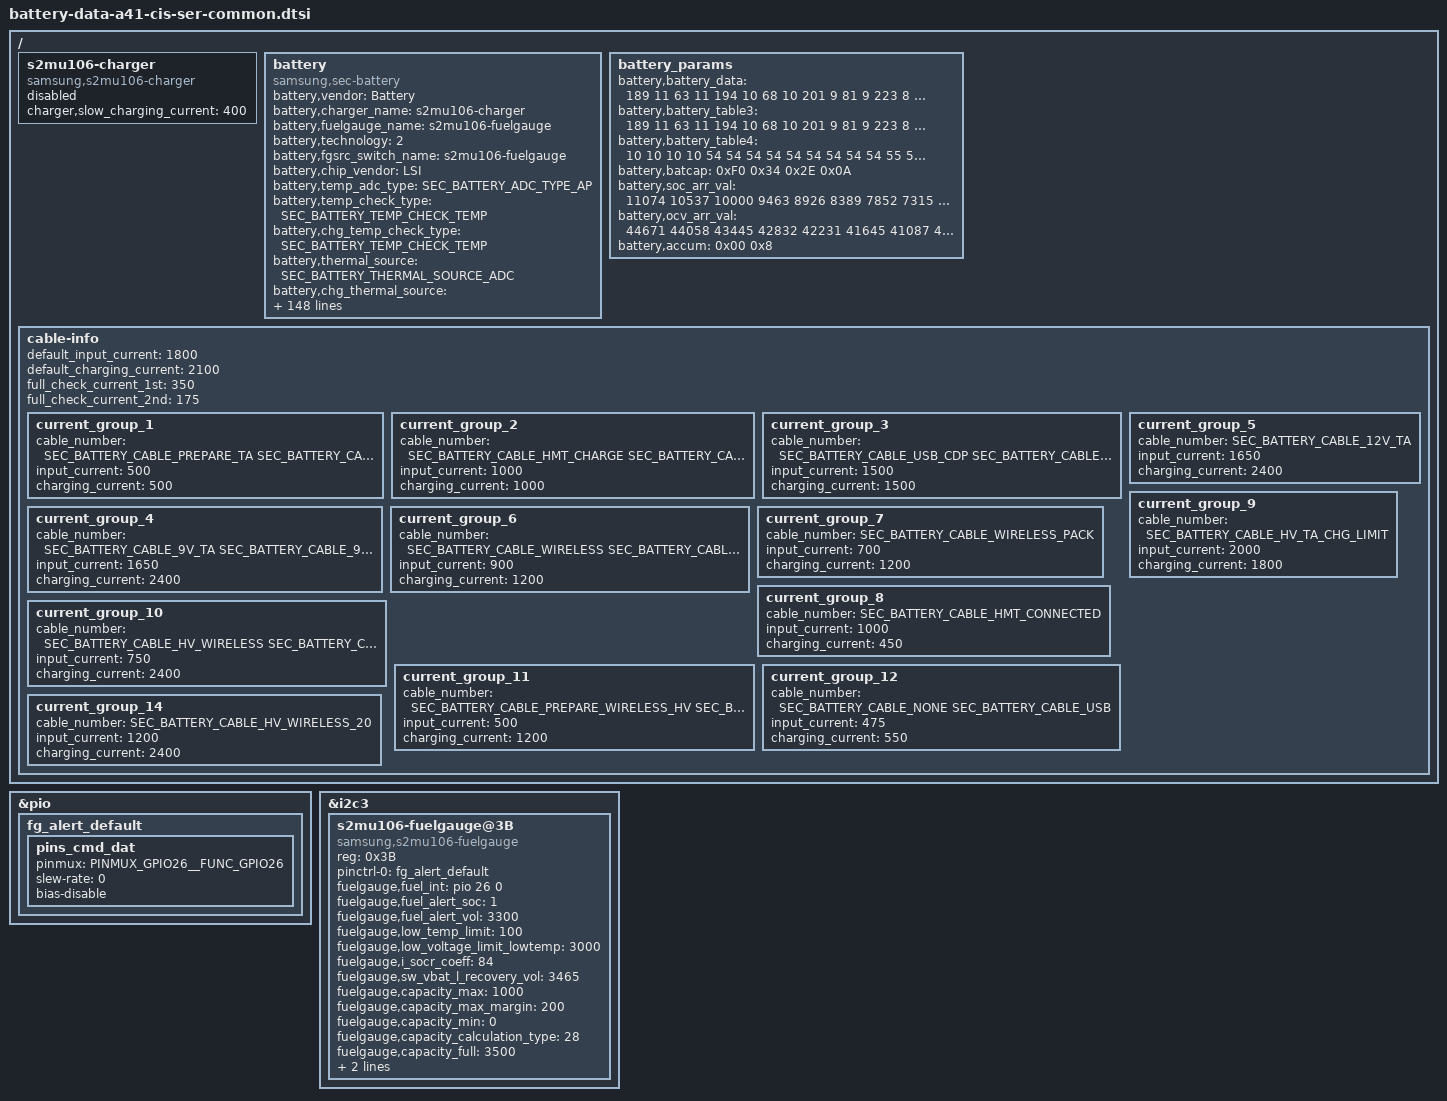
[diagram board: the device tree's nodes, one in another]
/*
 * A41 MTK 2019 Battery parameters device tree file
 *
 * Copyright (C) 2019 Samsung Electronics, Inc.
 *
 * This program is free software: you can redistribute it and/or
 * modify it under the terms of the GNU General Public License
 * as published by the Free Software Foundation; either version 2
 * of the License, or (at your option) any later version.
 *
 * This program is distributed in the hope that it will be useful,
 * but WITHOUT ANY WARRANTY; without even the implied warranty of
 * MERCHANTABILITY or FITNESS FOR A PARTICULAR PURPOSE. See the
 * GNU General Public License for more details.
 *
 * You should have received a copy of the GNU General Public License
 * along with this program. If not, see <http://www.gnu.org/licenses/>.
 *
 */
#include <dt-bindings/battery/sec_battery_param_define.h>

&pio {
	fg_alert_default: fg_alert_default {
		pins_cmd_dat {
			pinmux = <PINMUX_GPIO26__FUNC_GPIO26>;
			slew-rate = <0>;
			bias-disable;
		};
	};
};

&i2c3 {
	s2mu106-fuelgauge@3B {
		status = "okay";
		compatible = "samsung,s2mu106-fuelgauge";
		reg = <0x3B>;
		pinctrl-names = "fg_alrt_default";
		pinctrl-0 = <&fg_alert_default>;
		fuelgauge,fuel_int = <&pio 26 0>;
		fuelgauge,fuel_alert_soc = <1>;
		fuelgauge,fuel_alert_vol = <3300>;
		fuelgauge,low_temp_limit = <100>;
		fuelgauge,low_voltage_limit_lowtemp = <3000>;
		fuelgauge,i_socr_coeff = <84>;
		fuelgauge,sw_vbat_l_recovery_vol = <3465>;
		fuelgauge,capacity_max = <1000>;
		fuelgauge,capacity_max_margin = <200>;
		fuelgauge,capacity_min = <0>;
		fuelgauge,capacity_calculation_type = <28>;
		fuelgauge,capacity_full = <3500>;
		fuelgauge,type_str = "SDI";
		fuelgauge,fg_log_enable = <1>;
	};
};

/ {
	fragment@battery {
		target-path = "/";
		__overlay__ {
			s2mu106-charger {
				status = "disable";
				compatible = "samsung,s2mu106-charger";
				charger,slow_charging_current = <400>;
			};

			battery {
				status = "okay";
				compatible = "samsung,sec-battery";

				pinctrl-names = "default";

				battery,vendor = "Battery";
				battery,charger_name = "s2mu106-charger";
				battery,fuelgauge_name = "s2mu106-fuelgauge";
				battery,technology = <2>; /* POWER_SUPPLY_TECHNOLOGY_LION */
				battery,fgsrc_switch_name = "s2mu106-fuelgauge"; /* Fuelgauge voltage source */

				battery,chip_vendor = "LSI";
				battery,temp_adc_type = <SEC_BATTERY_ADC_TYPE_AP>;

				battery,temp_check_type = <SEC_BATTERY_TEMP_CHECK_TEMP>;
				battery,chg_temp_check_type = <SEC_BATTERY_TEMP_CHECK_TEMP>;

				battery,thermal_source = <SEC_BATTERY_THERMAL_SOURCE_ADC>;
				battery,chg_thermal_source = <SEC_BATTERY_THERMAL_SOURCE_FG>;

				battery,polling_time = <10 30 30 30 3600>;

				battery,temp_table_adc = <
							117 142 196 234 275 323 392 474 568 617
							676 825 922 993 1170 1440 1715 2005 2132 2332
							2522 2672 2962 3335 3584
							>;
				battery,temp_table_data = <
							850 800 700 650 600 550 500 450 400 370
							350 300 270 250 200 150 100 50 30 0
							(-30) (-50) (-100) (-150) (-200)
							>;

				battery,inbat_voltage = <SEC_BATTERY_ADC_TYPE_NONE>;

				battery,adc_check_count = <5>;

				battery,cable_check_type = <SEC_BATTERY_CABLE_CHECK_PSY>;
				battery,cable_source_type = <SEC_BATTERY_CABLE_SOURCE_EXTERNAL>;
				battery,polling_type = <SEC_BATTERY_MONITOR_ALARM>;
				battery,monitor_initial_count = <0>;

				battery,pre_afc_input_current = <500>;
				battery,prepare_afc_delay = <0>;

				battery,battery_check_type = <0>; /* SEC_BATTERY_CHECK_NONE */
				battery,check_count = <0>;

				battery,ovp_uvlo_check_type = <SEC_BATTERY_OVP_UVLO_CHGPOLLING>;

				battery,temp_check_count = <1>;
				battery,overheatlimit_threshold = <700>;
				battery,overheatlimit_recovery = <680>;
				battery,usb_protection_temp = <610>;
				battery,temp_gap_bat_usb = <200>;

				battery,wire_warm_overheat_thresh = <500>;
				battery,wire_normal_warm_thresh = <410>;
				battery,wire_cool1_normal_thresh = <150>;
				battery,wire_cool2_cool1_thresh = <150>;
				battery,wire_cool3_cool2_thresh = <50>;
				battery,wire_cold_cool3_thresh = <0>;

				battery,wireless_warm_overheat_thresh = <450>;
				battery,wireless_normal_warm_thresh = <410>;
				battery,wireless_cool1_normal_thresh = <150>;
				battery,wireless_cool2_cool1_thresh = <150>;
				battery,wireless_cool3_cool2_thresh = <50>;
				battery,wireless_cold_cool3_thresh = <0>;

				battery,wire_warm_current = <1200>;		/* 0.36C */
				battery,wire_cool1_current = <2400>;		/* 0.72C 1st step not used */
				battery,wire_cool2_current = <800>;		/* 0.3C */
				battery,wire_cool3_current = <300>;		/* 0.1C */

				battery,wireless_warm_current = <800>;		/* 0.24C */
				battery,wireless_cool1_current = <2400>;	/* 0.72C */
				battery,wireless_cool2_current = <800>;		/* 0.3C */
				battery,wireless_cool3_current = <450>;		/* 0.1C */

				battery,high_temp_topoff = <175>;
				battery,low_temp_topoff = <175>;
				battery,high_temp_float = <4150>;
				battery,low_temp_float = <4380>;

				battery,swelling_high_rechg_voltage = <4000>;
				battery,swelling_low_rechg_voltage = <4200>;

				battery,full_check_type = <SEC_BATTERY_FULLCHARGED_FG_CURRENT>;
				battery,full_check_type_2nd = <SEC_BATTERY_FULLCHARGED_FG_CURRENT>;
				battery,full_check_count = <1>;
				battery,chg_gpio_full_check = <0>;
				battery,chg_polarity_full_check = <1>;

				battery,chg_heating_prevention_method = <1>; /* SEC_BATTERY_BY_CHANGING_CURRENT */
				battery,chg_high_temp = <460>;
				battery,chg_high_temp_recovery = <440>;
				battery,chg_input_limit_current = <1000>;
				battery,chg_charging_limit_current = <1250>; 

				battery,wpc_high_temp = <410>;
				battery,wpc_high_temp_recovery = <400>;
				battery,wpc_charging_limit_current = <450>;
				battery,wpc_lcd_on_high_temp = <430>;
				battery,wpc_lcd_on_high_temp_rec = <300>;

				battery,wpc_store_high_temp = <410>;
				battery,wpc_store_high_temp_recovery = <400>;
				battery,wpc_store_lcd_on_high_temp = <380>;
				battery,wpc_store_lcd_on_high_temp_rec = <300>;

				battery,sleep_mode_limit_current = <500>;
				battery,wc_full_input_limit_current = <100>;
				battery,wc_cv_current = <820>;
				battery,wc_cv_pack_current = <630>;
				battery,wc_hero_stand_cc_cv = <70>;
				battery,wc_hero_stand_cv_current = <600>;
				battery,wc_hero_stand_hv_cv_current = <450>;

				battery,mix_high_temp = <420>;
				battery,mix_high_chg_temp = <500>;
				battery,mix_high_temp_recovery = <390>;
				
				/* SEC_BATTERY_FULL_CONDITION_SOC |
				* SEC_BATTERY_FULL_CONDITION_NOTIMEFULL |
				* SEC_BATTERY_FULL_CONDITION_VCELL
				*/
				battery,full_condition_type = <13>;
				battery,full_condition_soc = <93>;
				battery,full_condition_vcell = <4280>;

				battery,recharge_check_count = <1>;
				battery,recharge_condition_type = <SEC_BATTERY_RECHARGE_CONDITION_VCELL>;
				battery,recharge_condition_soc = <98>;
				battery,recharge_condition_vcell = <4310>;

				battery,charging_total_time = <14400>;
				battery,hv_charging_total_time = <10800>;
				battery,normal_charging_total_time = <18000>;
				battery,usb_charging_total_time = <36000>;
				battery,recharging_total_time = <5400>;
				battery,charging_reset_time = <0>;
				battery,chg_float_voltage = <4380>;
				battery,chg_float_voltage_conv = <1>;

				battery,siop_event_check_type = <1>;
				battery,siop_call_cv_current = <330>;
				battery,siop_call_cc_current = <330>;

				battery,siop_input_limit_current = <1200>;
				battery,siop_charging_limit_current = <1000>;
				battery,siop_hv_input_limit_current = <700>;
				battery,siop_hv_charging_limit_current = <1000>;

				battery,input_current_by_siop_20 = <1000>;
				battery,hv_input_current_by_siop_20 = <500>;
				battery,input_current_by_siop_10 = <800>;
				battery,hv_input_current_by_siop_10 = <400>;
				battery,input_current_by_siop_0 = <1000>;
				battery,hv_input_current_by_siop_0 = <500>;

				battery,siop_wireless_input_limit_current = <600>;
				battery,siop_wireless_charging_limit_current = <700>;
				battery,siop_hv_wireless_input_limit_current = <600>;
				battery,siop_hv_wireless_charging_limit_current = <700>;
				battery,siop_store_hv_wireless_input_limit_current = <450>;

				battery,ttf_hv_charge_current = <2400>;
				battery,ttf_hv_wireless_charge_current = <1050>;
				battery,ttf_wireless_charge_current = <900>;
				
				battery,rp_current_rp1 = <500>;
				battery,rp_current_rp2 = <1500>;
				battery,rp_current_rp3 = <3000>;
				battery,rp_current_rdu_rp3 = <2100>;
				battery,rp_current_abnormal_rp3 = <1800>;

				battery,pd_charging_charge_power = <15000>;
				battery,max_charging_current = <2400>;
				battery,max_charging_charge_power = <25000>; /* 25W */

				/* cycle, chg_float_voltage, recharge_condition_vcell, full_condition_vcell, full_condition_soc, step charging condition */
				battery,age_data = <0 4380 4310 4280 93
					300 4360 4290 4260 92
					400 4340 4270 4240 91
					700 4320 4250 4220 90
					1000 4270 4200 4170 89>;

				battery,health_condition = <
						/* CYCLE ASOC */
						900 75	/* GOOD */
						1200 65 /* NORMAL */
						1500 55 /* AGED */
						>;

				battery,max_input_voltage = <9000>; /* mV */
				battery,max_input_current = <3000>;  /* mA */

				battery,standard_curr = <2400>;
				battery,expired_time = <10800>; /* 120 + 60 minutes */
				battery,recharging_expired_time = <5400>;
				battery,battery_full_capacity = <3500>;
				battery,cisd_max_voltage_thr = <5000>; /* batttery ovp dettection voltage */
				battery,cisd_alg_index = <8>;
				battery,ignore_cisd_index = <0 960>; /* Do not use AFC_FAIL to DROP_VALUE */
				battery,ignore_cisd_index_d = <0 120>; /* Do not use AFC_FAIL_PER_DAY to DROP_VALUE_PER_DAY */ 

				io-channels = <&auxadc 3>;
				io-channel-names = "adc-temp";
			};

			battery_params {
				battery,battery_data =
					<
					/***** battery data for 4.38 *****/
					/* battery,battery_table3 */
					189 11 63 11 194 10 68 10 201 9
					81 9 223 8 117 8 20 8 190 7
					83 7 247 6 191 6 147 6 112 6
					82 6 41 6 251 5 197 5 141 5
					82 5 182 1 220 8 110 8 0 8
					146 7 36 7 182 6 72 6 218 5
					108 5 254 4 144 4 34 4 180 3
					70 3 216 2 106 2 252 1 142 1
					32 1 178 0 68 0 217 15

					/* battery,battery_table4 */
					10 10 10 10 54 54 54 54 54 54
					54 54 54 55 56 56 57 57 57 59
					61 154

					/* battery,batcap */
					0xF0 0x34 0x2E 0x0A /* [0x0E] [0x0F] [0x10] [0x11] */
					/* battery,accum */
					0x00 0x08 /* [0x44] [0x45] */

					/* battery,soc_arr_val */
					11074 10537 10000 9463 8926 8389 7852 7315 6777 6240
					5703 5166 4629 4091 3554 3017 2480 1943 1406 868
					331 (-191)

					/* battery,ocv_arr_val */
					44671 44058 43445 42832 42231 41645 41087 40570 40098 39676
					39153 38707 38434 38218 38046 37900 37700 37474 37212 36939
					36652 32139

					/* battery,tunning */
					0x00

					/***** battery data for 4.36 *****/
					/* battery,battery_table3 */
					189 11 63 11 194 10 68 10 201 9
					81 9 223 8 117 8 20 8 190 7
					83 7 247 6 191 6 147 6 112 6
					82 6 41 6 251 5 197 5 141 5
					82 5 182 1 255 8 144 8 32 8
					176 7 64 7 209 6 97 6 241 5
					130 5 18 5 162 4 50 4 195 3
					83 3 227 2 116 2 4 2 148 1
					36 1 181 0 69 0 216 15

					/* battery,battery_table4 */
					10 10 10 10 54 54 54 54 54 54
					54 54 54 55 56 56 57 57 57 59
					61 154

					/* battery,batcap */
					0x28 0x32 0x86 0x07  /* [0x0E] [0x0F] [0x10] [0x11] */
					/* battery,accum */
					0x00 0x8 /* [0x44] [0x45] */

					/* battery,soc_arr_val */
					11247 10701 10156 9610 9065 8519 7974 7428 6883 6337
					5792 5246 4701 4155 3610 3064 2519 1973 1428 882
					336 (-194)
					/* battery,ocv_arr_val */
					44671 44058 43445 42832 42231 41645 41087 40570 40098 39676
					39153 38707 38434 38218 38046 37900 37700 37474 37212 36939
					36652 32139

					/* battery,tunning */
					0x00

					/***** battery data for 4.34 *****/
					/* battery,battery_table3 */
					189 11 63 11 194 10 68 10 201 9
					81 9 223 8 117 8 20 8 190 7
					83 7 247 6 191 6 147 6 112 6
					82 6 41 6 251 5 197 5 141 5
					82 5 182 1 39 9 182 8 68 8
					210 7 97 7 239 6 125 6 12 6
					154 5 41 5 183 4 69 4 211 3
					98 3 240 2 126 2 13 2 155 1
					42 1 184 0 70 0 216 15

					/* battery,battery_table4 */
					10 10 10 10 54 54 54 54 54 54
					54 54 54 55 56 56 57 57 57 59
					61 154

					/* battery,batcap */
					0x4C 0x31 0x65 0x07 /* [0x0E] [0x0F] [0x10] [0x11] */
					/* battery,accum */
					0x00 0x8 /* [0x44] [0x45] */

					/* battery,soc_arr_val */
					11442 10887 10332 9778 9223 8668 8113 7558 7003 6448
					5893 5337 4782 4227 3673 3118 2563 2008 1453 897
					342 (-197)
					/* battery,ocv_arr_val */
					44671 44058 43445 42832 42231 41645 41087 40570 40098 39676
					39153 38707 38434 38218 38046 37900 37700 37474 37212 36939
					36652 32139

					/* battery,tunning */
					0x00

					/***** battery data for 4.32 *****/
					/* battery,battery_table3 */
					189 11 63 11 194 10 68 10 201 9
					81 9 223 8 117 8 20 8 190 7
					83 7 247 6 191 6 147 6 112 6
					82 6 41 6 251 5 197 5 141 5
					82 5 182 1 85 9 225 8 109 8
					249 7 133 7 18 7 158 6 42 6
					182 5 66 5 206 4 90 4 230 3
					115 3 255 2 139 2 23 2 163 1
					47 1 187 0 71 0 215 15

					/* battery,battery_table4 */
					10 10 10 10 54 54 54 54 54 54
					54 54 54 55 56 56 57 57 57 59
					61 154

					/* battery,batcap */
					0x5C 0x30 0x41 0x07 /* [0x0E] [0x0F] [0x10] [0x11] */
					/* battery,accum */
					0x00 0x8 /* [0x44] [0x45] */

					/* battery,soc_arr_val */
					11664 11098 10533 9967 9401 8836 8270 7704 7138 6573
					6007 5441 4875 4309 3744 3178 2612 2047 1481 915
					349 (-201)
					/* battery,ocv_arr_val */
					44671 44058 43445 42832 42231 41645 41087 40570 40098 39676
					39153 38707 38434 38218 38046 37900 37700 37474 37212 36939
					36652 32139

					/* battery,tunning */
					0x00

					/***** battery data for 4.27 *****/
					/* battery,battery_table3 */
					189 11 63 11 194 10 68 10 201 9
					81 9 223 8 117 8 20 8 190 7
					83 7 247 6 191 6 147 6 112 6
					82 6 41 6 251 5 197 5 141 5
					82 5 182 1 202 9 81 9 215 8
					93 8 228 7 106 7 241 6 119 6
					254 5 132 5 11 5 145 4 23 4
					158 3 36 3 171 2 49 2 184 1
					62 1 196 0 75 0 213 15

					/* battery,battery_table4 */
					10 10 10 10 54 54 54 54 54 54
					54 54 54 55 56 56 57 57 57 59
					61 154

					/* battery,batcap */
					0x18 0x2E 0xEA 0x06 /* [0x0E] [0x0F] [0x10] [0x11] */
					/* battery,accum */
					0x00 0x8 /* [0x44] [0x45] */

					/* battery,soc_arr_val */
					12237 11643 11050 10456 9863 9269 8676 8082 7489 6895
					6302 5708 5114 4521 3927 3334 2741 2147 1554 959
					366 (-211)
					/* battery,ocv_arr_val */
					44671 44058 43445 42832 42231 41645 41087 40570 40098 39676
					39153 38707 38434 38218 38046 37900 37700 37474 37212 36939
					36652 32139

					/* battery,tunning */
					0x00
				>;

				battery,battery_table3 = <
						189 11 63 11 194 10 68 10 201 9
						81 9 223 8 117 8 20 8 190 7
						83 7 247 6 191 6 147 6 112 6
						82 6 41 6 251 5 197 5 141 5
						82 5 182 1 220 8 110 8 0 8
						146 7 36 7 182 6 72 6 218 5
						108 5 254 4 144 4 34 4 180 3
						70 3 216 2 106 2 252 1 142 1
						32 1 178 0 68 0 217 15
						>;

				battery,battery_table4 = <
						10 10 10 10 54 54 54 54 54 54
						54 54 54 55 56 56 57 57 57 59
						61 154
						>;

				battery,batcap = <0xF0 0x34 0x2E 0x0A>; /* [0x0E] [0x0F] [0x10] [0x11] */

				battery,soc_arr_val = <
							11074 10537 10000 9463 8926 8389 7852 7315 6777 6240
							5703 5166 4629 4091 3554 3017 2480 1943 1406 868
							331 (-191)
							>;
				battery,ocv_arr_val = <
							44671 44058 43445 42832 42231 41645 41087 40570 40098 39676
							39153 38707 38434 38218 38046 37900 37700 37474 37212 36939
							36652 32139
							>;

				battery,accum = <0x00 0x8>; /* 0x44 0x45 */
			};
			/* sec_battery_cable
			 *   0	UNKNOWN,
			 *   1	NONE,
			 *   2	PREPARE_TA,
			 *   3	TA,
			 *   4	USB,
			 *   5	USB_CDP,
			 *   6	9V_TA,
			 *   7	9V_ERR,
			 *   8	9V_UNKNOWN,
			 *   9	12V_TA,
			 *  10	WIRELESS,
			 *  11	HV_WIRELESS,
			 *  12	PMA_WIRELESS,
			 *  13	WIRELESS_PACK,
			 *  14	CABLE_WIRELESS_HV_PACK,
			 *  15	WIRELESS_STAND,
			 *  16	WIRELESS_HV_STAND,
			 *  17	QC20,
			 *  18	QC30,
			 *  19	PDIC,
			 *  20	UARTOFF,
			 *  21	OTG,
			 *  22	LAN_HUB,
			 *  23	POWER_SHARING,
			 *  24	HMT_CONNECTED,
			 *  25	HMT_CHARGE,
			 *  26	HV_TA_CHG_LIMIT,
			 *  27	WIRELESS_VEHICLE,
			 *  28	WIRELESS_HV_VEHICLE,
			 *  29	PREPARE_WIRELESS_HV,
			 *  30  TIMEOUT,
			 *  31  SMART_OTG,
			 *  32  SMART_NOTG,
			 *  33  WIRELESS_TX,
			 *  34	HV_WIRELESS_20,
			 *  35	HV_WIRELESS_20_LIMIT,
			 *  36	WIRELESS_FAKE,
			 *  37  PREPARE_WIRELESS_20,
			 *  38	CABLE_PDIC_APDO,
			 *  39	CABLE_MAX,
			 */
			cable-info {
				default_input_current = <1800>;
				default_charging_current = <2100>;
				full_check_current_1st = <350>;
				full_check_current_2nd = <175>;

				current_group_1 {
					cable_number = <
						SEC_BATTERY_CABLE_PREPARE_TA
						SEC_BATTERY_CABLE_PDIC
						SEC_BATTERY_CABLE_OTG
						SEC_BATTERY_CABLE_LAN_HUB
						SEC_BATTERY_CABLE_POWER_SHARING
						SEC_BATTERY_CABLE_TIMEOUT>;
					input_current = <500>;
					charging_current = <500>;
				};
				current_group_2 {
					cable_number = <
						SEC_BATTERY_CABLE_HMT_CHARGE
						SEC_BATTERY_CABLE_SMART_OTG>;
					input_current = <1000>;
					charging_current = <1000>;
				};
				current_group_3 {
					cable_number = <
						SEC_BATTERY_CABLE_USB_CDP
						SEC_BATTERY_CABLE_SMART_NOTG>;
					input_current = <1500>;
					charging_current = <1500>;
				};
				current_group_4 {
					cable_number = <
						SEC_BATTERY_CABLE_9V_TA
						SEC_BATTERY_CABLE_9V_ERR
						SEC_BATTERY_CABLE_9V_UNKNOWN
						SEC_BATTERY_CABLE_QC20
						SEC_BATTERY_CABLE_QC30>;
					input_current = <1650>;
					charging_current = <2400>;
				};
				current_group_5 {
					cable_number = <SEC_BATTERY_CABLE_12V_TA>;
					input_current = <1650>;
					charging_current = <2400>;
				};
				current_group_6 {
					cable_number = <
						SEC_BATTERY_CABLE_WIRELESS
						SEC_BATTERY_CABLE_PMA_WIRELESS
						SEC_BATTERY_CABLE_WIRELESS_STAND
						SEC_BATTERY_CABLE_WIRELESS_VEHICLE
						SEC_BATTERY_CABLE_WIRELESS_TX
						SEC_BATTERY_CABLE_WIRELESS_FAKE>;
					input_current = <900>;
					charging_current = <1200>;
				};
				current_group_7 {
					cable_number = <SEC_BATTERY_CABLE_WIRELESS_PACK>;
					input_current = <700>;
					charging_current = <1200>;
				};
				current_group_8 {
					cable_number = <SEC_BATTERY_CABLE_HMT_CONNECTED>;
					input_current = <1000>;
					charging_current = <450>;
				};
				current_group_9 {
					cable_number = <SEC_BATTERY_CABLE_HV_TA_CHG_LIMIT>;
					input_current = <2000>;
					charging_current = <1800>;
				};
				current_group_10 {
					cable_number = <
						SEC_BATTERY_CABLE_HV_WIRELESS
						SEC_BATTERY_CABLE_WIRELESS_HV_PACK
						SEC_BATTERY_CABLE_WIRELESS_HV_STAND
						SEC_BATTERY_CABLE_WIRELESS_HV_VEHICLE
						SEC_BATTERY_CABLE_HV_WIRELESS_20_LIMIT>;
					input_current = <750>;
					charging_current = <2400>;
				};
				current_group_11 {
					cable_number = <
						SEC_BATTERY_CABLE_PREPARE_WIRELESS_HV
						SEC_BATTERY_CABLE_PREPARE_WIRELESS_20>;
					input_current = <500>;
					charging_current = <1200>;
				};
				current_group_12 {
					cable_number = <
						SEC_BATTERY_CABLE_NONE
						SEC_BATTERY_CABLE_USB>;
					input_current = <475>;
					charging_current = <550>;
				};
				current_group_14 {
					cable_number = <SEC_BATTERY_CABLE_HV_WIRELESS_20>;
					input_current = <1200>;
					charging_current = <2400>;
				};
			};
		};
	};
};
